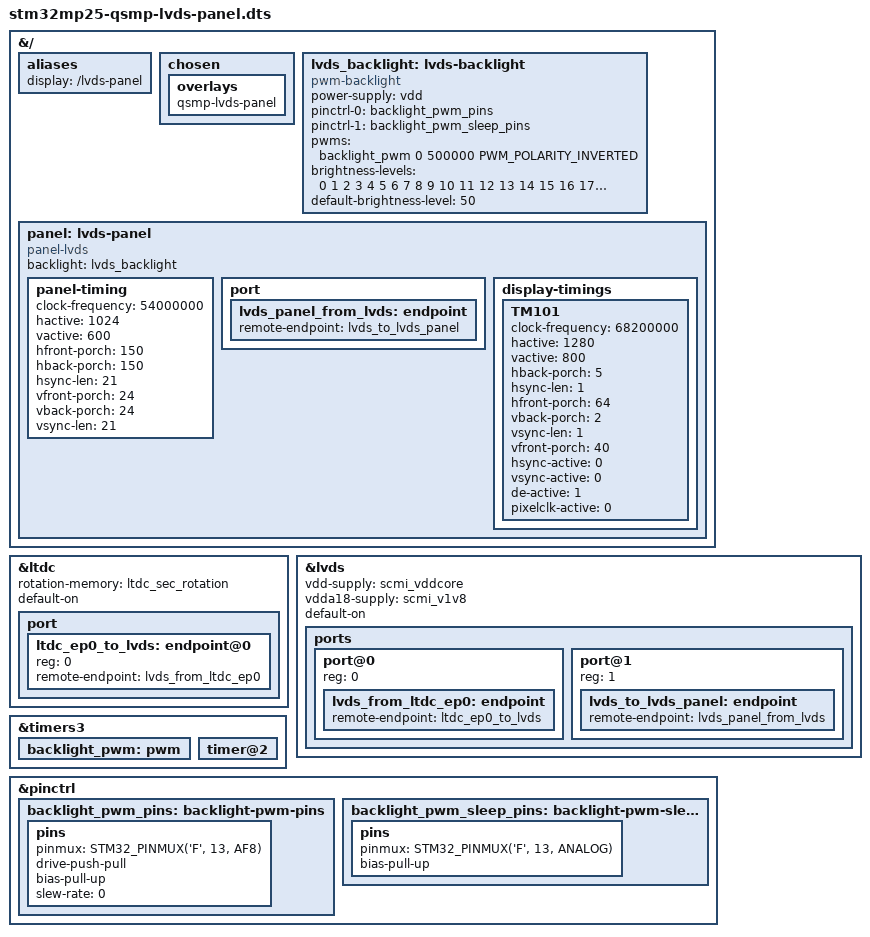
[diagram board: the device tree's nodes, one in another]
// SPDX-License-Identifier: (GPL-2.0-only OR BSD-3-Clause)
/*
 * Copyright (C) 2024 Lothar Waßmann <LW@KARO-electronics.de>
 */

/dts-v1/;
/plugin/;

#include <dt-bindings/gpio/gpio.h>
#include <dt-bindings/pinctrl/stm32-pinfunc.h>
#include <dt-bindings/pwm/pwm.h>

&{/} {
	aliases {
		display = "/lvds-panel";
	};

	chosen {
		overlays {
			qsmp-lvds-panel;
		};
	};

	lvds_backlight: lvds-backlight {
		compatible = "pwm-backlight";
		power-supply = <&vdd>;
		pinctrl-0 = <&backlight_pwm_pins>;
		pinctrl-1 = <&backlight_pwm_sleep_pins>;
		pwms = <&backlight_pwm 0 500000 PWM_POLARITY_INVERTED>;
		brightness-levels = <0 1  2  3  4  5  6  7  8  9  10
				     11 12 13 14 15 16 17 18 19  20
				     21 22 23 24 25 26 27 28 29  30
				     31 32 33 34 35 36 37 38 39  40
				     41 42 43 44 45 46 47 48 49  50
				     51 52 53 54 55 56 57 58 59  60
				     61 62 63 64 65 66 67 68 69  70
				     71 72 73 74 75 76 77 78 79  80
				     81 82 83 84 85 86 87 88 89  90
				     91 92 93 94 95 96 97 98 99 100
				    >;
		default-brightness-level = <50>;
		status = "okay";
	};

	panel: lvds-panel {
		compatible = "panel-lvds";
		backlight = <&lvds_backlight>;
		status = "okay";

		panel-timing {
			clock-frequency = <54000000>;
			hactive = <1024>;
			vactive = <600>;
			hfront-porch = <150>;
			hback-porch = <150>;
			hsync-len = <21>;
			vfront-porch = <24>;
			vback-porch = <24>;
			vsync-len = <21>;
		};

		port {
			lvds_panel_from_lvds: endpoint {
				remote-endpoint = <&lvds_to_lvds_panel>;
			};
		};

		display-timings {
			TM101: TM101 {
				clock-frequency = <68200000>;
				hactive = <1280>;
				vactive = <800>;
				hback-porch = <5>;
				hsync-len = <1>;
				hfront-porch = <64>;
				vback-porch = <2>;
				vsync-len = <1>;
				vfront-porch = <40>;
				hsync-active = <0>;
				vsync-active = <0>;
				de-active = <1>;
				pixelclk-active = <0>;
			};
		};
	};
};

&ltdc {
	rotation-memory = <&ltdc_sec_rotation>;
	default-on;
	status = "okay";

	port {
		#address-cells = <1>;
		#size-cells = <0>;

		ltdc_ep0_to_lvds: endpoint@0 {
			reg = <0>;
			remote-endpoint = <&lvds_from_ltdc_ep0>;
		};
	};
};

&lvds {
	vdd-supply =  <&scmi_vddcore>;
	vdda18-supply = <&scmi_v1v8>;
	default-on;
	status = "okay";

	ports {
		#address-cells = <1>;
		#size-cells = <0>;

		port@0 {
			reg = <0>;

			lvds_from_ltdc_ep0: endpoint {
				remote-endpoint = <&ltdc_ep0_to_lvds>;
			};
		};

		port@1 {
			reg = <1>;

			lvds_to_lvds_panel: endpoint {
				remote-endpoint = <&lvds_panel_from_lvds>;
			};
		};
	};
};

&timers3 {
	/delete-property/ dmas;
	/delete-property/ dma-names;
	status = "okay";

	backlight_pwm: pwm {
		status = "okay";
	};

	timer@2 {
		status = "okay";
	};
};

&pinctrl {
	backlight_pwm_pins: backlight-pwm-pins {
		pins {
			pinmux = <STM32_PINMUX('F', 13, AF8)>; /* TIM3_CH3 */
			drive-push-pull;
			/*
			 * pull PWM output HIGH when PWM is disabled;
			 * change to 'bias-pull-down' when LCD backlight pin is active HIGH
			 */
			bias-pull-up;
			slew-rate = <0>;
		};
	};

	backlight_pwm_sleep_pins: backlight-pwm-sleep-pins {
		pins {
			pinmux = <STM32_PINMUX('F', 13, ANALOG)>; /* TIM3_CH3 */
			/*
			 * pull PWM output HIGH when PWM is disabled;
			 * change to 'bias-pull-down' when LCD backlight pin is active HIGH
			 */
			bias-pull-up;
		};
	};
};
